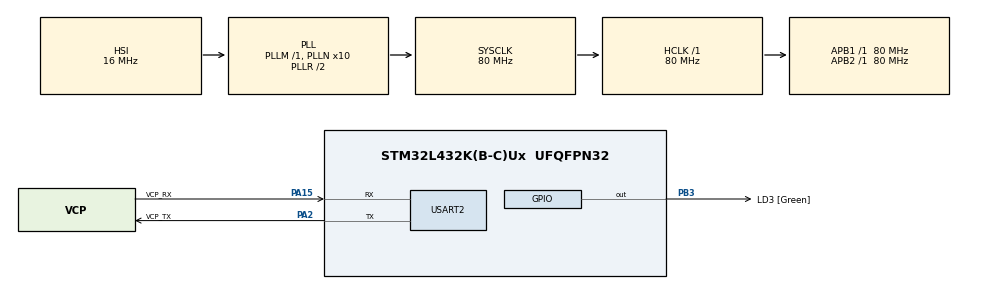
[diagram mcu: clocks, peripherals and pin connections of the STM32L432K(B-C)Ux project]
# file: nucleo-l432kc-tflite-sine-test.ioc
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Mcu.Family=STM32L4
Mcu.Name=STM32L432K(B-C)Ux
Mcu.Package=UFQFPN32
NVIC.PriorityGroup=NVIC_PRIORITYGROUP_4
PA0.GPIO_Label=MCO [High speed clock in]
PA0.Mode=HSE-External-Clock-Source-for-LittleOrca
PA0.Signal=RCC_CK_IN
PA13\ (JTMS-SWDIO).GPIO_Label=SWDIO
PA13\ (JTMS-SWDIO).Mode=Serial_Wire
PA13\ (JTMS-SWDIO).Signal=SYS_JTMS-SWDIO
PA14\ (JTCK-SWCLK).GPIO_Label=SWCLK
PA14\ (JTCK-SWCLK).Mode=Serial_Wire
PA14\ (JTCK-SWCLK).Signal=SYS_JTCK-SWCLK
PA15\ (JTDI).GPIO_Label=VCP_RX
PA15\ (JTDI).Mode=Asynchronous
PA15\ (JTDI).Signal=USART2_RX
PA2.GPIO_Label=VCP_TX
PA2.Mode=Asynchronous
PA2.Signal=USART2_TX
PB3\ (JTDO-TRACESWO).GPIO_Label=LD3 [Green]
PB3\ (JTDO-TRACESWO).Signal=GPIO_Output
PC14-OSC32_IN\ (PC14).Mode=LSE-External-Oscillator
PC14-OSC32_IN\ (PC14).Signal=RCC_OSC32_IN
PC15-OSC32_OUT\ (PC15).Mode=LSE-External-Oscillator
PC15-OSC32_OUT\ (PC15).Signal=RCC_OSC32_OUT
ProjectManager.HeapSize=0x200
ProjectManager.StackSize=0x400
ProjectManager.TargetToolchain=STM32CubeIDE
RCC.ADCFreq_Value=64000000
RCC.AHBFreq_Value=80000000
RCC.APB1Freq_Value=80000000
RCC.APB1TimFreq_Value=80000000
RCC.APB2Freq_Value=80000000
RCC.APB2TimFreq_Value=80000000
RCC.CortexFreq_Value=80000000
RCC.HCLKFreq_Value=80000000
RCC.HSE_VALUE=8000000
RCC.HSI16_VALUE=16000000
RCC.HSI48_VALUE=48000000
RCC.HSI_VALUE=16000000
RCC.MSI_VALUE=4000000
RCC.PLLMUL=RCC_PLLMUL_4
RCC.PLLN=10
RCC.PLLSourceVirtual=RCC_PLLSOURCE_HSI
RCC.SYSCLKFreq_VALUE=80000000
RCC.SYSCLKSource=RCC_SYSCLKSOURCE_PLLCLK
RCC.USBFreq_Value=64000000
RCC.VCOOutputFreq_Value=160000000
TIM16.Prescaler=80 - 1
USART2.VirtualMode-Asynchronous=VM_ASYNC
VP_TIM16_VS_ClockSourceINT.Mode=Enable_Timer
board=NUCLEO-L432KC

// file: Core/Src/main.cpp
/* USER CODE BEGIN Header */
/**
  ******************************************************************************
  * @file           : main.c
  * @brief          : Main program body
  ******************************************************************************
  * @attention
  *
  * <h2><center>&copy; Copyright (c) 2021 STMicroelectronics.
  * All rights reserved.</center></h2>
  *
  * This software component is licensed by ST under BSD 3-Clause license,
  * the "License"; You may not use this file except in compliance with the
  * License. You may obtain a copy of the License at:
  *                        opensource.org/licenses/BSD-3-Clause
  *
  ******************************************************************************
  */
/* USER CODE END Header */
#include "main.h"

/* USER CODE BEGIN Includes */
#include <string.h>

#include "tensorflow/lite/micro/kernels/micro_ops.h"
#include "tensorflow/lite/micro/micro_error_reporter.h"
#include "tensorflow/lite/micro/micro_interpreter.h"
#include "tensorflow/lite/micro/micro_mutable_op_resolver.h"
#include "tensorflow/lite/version.h"
#include "sine_model.h"
/* USER CODE END Includes */

TIM_HandleTypeDef htim16;

UART_HandleTypeDef huart2;

/* USER CODE BEGIN PV */

// TFLite globals
namespace {
  tflite::ErrorReporter* error_reporter = nullptr;
  const tflite::Model* model = nullptr;
  tflite::MicroInterpreter* interpreter = nullptr;
  TfLiteTensor* model_input = nullptr;
  TfLiteTensor* model_output = nullptr;

  // Create an area of memory to use for input, output, and other TensorFlow
  // arrays. You'll need to adjust this by compiling, running, and looking
  // for errors.
  constexpr int kTensorArenaSize = 2 * 1024;
  __attribute__((aligned(16)))uint8_t tensor_arena[kTensorArenaSize];
} // namespace

/* USER CODE END PV */

void SystemClock_Config(void);
static void MX_GPIO_Init(void);
static void MX_USART2_UART_Init(void);
static void MX_TIM16_Init(void);

int main(void)
{
  /* USER CODE BEGIN 1 */
  char buf[50];
  int buf_len = 0;
  TfLiteStatus tflite_status;
  uint32_t num_elements;
  uint32_t timestamp;
  float y_val;

  /* USER CODE END 1 */

  /* MCU Configuration--------------------------------------------------------*/

  /* Reset of all peripherals, Initializes the Flash interface and the Systick. */
  HAL_Init();

  /* Configure the system clock */
  SystemClock_Config();

  /* Initialize all configured peripherals */
  MX_GPIO_Init();
  MX_USART2_UART_Init();
  MX_TIM16_Init();
  /* USER CODE BEGIN 2 */

  // Start timer/counter
  HAL_TIM_Base_Start(&htim16);

  // Set up logging (modify tensorflow/lite/micro/debug_log.cc)
  static tflite::MicroErrorReporter micro_error_reporter;
  error_reporter = &micro_error_reporter;

  // Say something to test error reporter
  error_reporter->Report("STM32 TensorFlow Lite test");

  // Map the model into a usable data structure
  model = tflite::GetModel(sine_model);
  if (model->version() != TFLITE_SCHEMA_VERSION)
  {
    error_reporter->Report("Model version does not match Schema");
    while(1);
  }

  // Pull in only needed operations (should match NN layers). Template parameter
  // <n> is number of ops to be added. Available ops:
  // tensorflow/lite/micro/kernels/micro_ops.h
  static tflite::MicroMutableOpResolver<1> micro_op_resolver;

  // Add dense neural network layer operation
  // KennyKang 20210808
  //tflite_status = micro_op_resolver.AddBuiltin(
  //     tflite::BuiltinOperator_FULLY_CONNECTED,
  //     tflite::ops::micro::Register_FULLY_CONNECTED());
  tflite_status = micro_op_resolver.AddFullyConnected();
  if (tflite_status != kTfLiteOk)
  {
    error_reporter->Report("Could not add FULLY CONNECTED op");
    while(1);
  }

  // Build an interpreter to run the model with.
  static tflite::MicroInterpreter static_interpreter(
      model, micro_op_resolver, tensor_arena, kTensorArenaSize, error_reporter);
  interpreter = &static_interpreter;

  // Allocate memory from the tensor_arena for the model's tensors.
  tflite_status = interpreter->AllocateTensors();
  if (tflite_status != kTfLiteOk)
  {
    error_reporter->Report("AllocateTensors() failed");
    while(1);
  }

  // Assign model input and output buffers (tensors) to pointers
  model_input = interpreter->input(0);
  model_output = interpreter->output(0);

  // Get number of elements in input tensor
  num_elements = model_input->bytes / sizeof(float);
  buf_len = sprintf(buf, "Number of input elements: %lu\r\n", num_elements);
  HAL_UART_Transmit(&huart2, (uint8_t *)buf, buf_len, 100);

  /* USER CODE END 2 */

  /* Infinite loop */
  /* USER CODE BEGIN WHILE */
  while (1)
  {
	  // Fill input buffer (use test value)
	  for (uint32_t i = 0; i < num_elements; i++)
	  {
	     model_input->data.f[i] = 2.0f;
	  }

	  // Get current timestamp
	  timestamp = htim16.Instance->CNT;

	  // Run inference
	  tflite_status = interpreter->Invoke();
	  if (tflite_status != kTfLiteOk)
	  {
	     error_reporter->Report("Invoke failed");
	  }

	  // Read output (predicted y) of neural network
	  y_val = model_output->data.f[0];

	  // Print output of neural network along with inference time (microseconds)
	  buf_len = sprintf(buf,
	                    "Output: %f | Duration: %lu\r\n",
	                    y_val,
	                    htim16.Instance->CNT - timestamp);
	  HAL_UART_Transmit(&huart2, (uint8_t *)buf, buf_len, 100);

	  // Wait before doing it again
	  HAL_Delay(500);

    /* USER CODE END WHILE */

  }
}

void SystemClock_Config(void)
{
  RCC_OscInitTypeDef RCC_OscInitStruct = {0};
  RCC_ClkInitTypeDef RCC_ClkInitStruct = {0};

  /** Configure the main internal regulator output voltage
  */
  if (HAL_PWREx_ControlVoltageScaling(PWR_REGULATOR_VOLTAGE_SCALE1) != HAL_OK)
  {
    Error_Handler();
  }
  /** Initializes the RCC Oscillators according to the specified parameters
  * in the RCC_OscInitTypeDef structure.
  */
  RCC_OscInitStruct.OscillatorType = RCC_OSCILLATORTYPE_HSI;
  RCC_OscInitStruct.HSIState = RCC_HSI_ON;
  RCC_OscInitStruct.HSICalibrationValue = RCC_HSICALIBRATION_DEFAULT;
  RCC_OscInitStruct.PLL.PLLState = RCC_PLL_ON;
  RCC_OscInitStruct.PLL.PLLSource = RCC_PLLSOURCE_HSI;
  RCC_OscInitStruct.PLL.PLLM = 1;
  RCC_OscInitStruct.PLL.PLLN = 10;
  RCC_OscInitStruct.PLL.PLLP = RCC_PLLP_DIV7;
  RCC_OscInitStruct.PLL.PLLQ = RCC_PLLQ_DIV2;
  RCC_OscInitStruct.PLL.PLLR = RCC_PLLR_DIV2;
  if (HAL_RCC_OscConfig(&RCC_OscInitStruct) != HAL_OK)
  {
    Error_Handler();
  }
  /** Initializes the CPU, AHB and APB buses clocks
  */
  RCC_ClkInitStruct.ClockType = RCC_CLOCKTYPE_HCLK|RCC_CLOCKTYPE_SYSCLK
                              |RCC_CLOCKTYPE_PCLK1|RCC_CLOCKTYPE_PCLK2;
  RCC_ClkInitStruct.SYSCLKSource = RCC_SYSCLKSOURCE_PLLCLK;
  RCC_ClkInitStruct.AHBCLKDivider = RCC_SYSCLK_DIV1;
  RCC_ClkInitStruct.APB1CLKDivider = RCC_HCLK_DIV1;
  RCC_ClkInitStruct.APB2CLKDivider = RCC_HCLK_DIV1;

  if (HAL_RCC_ClockConfig(&RCC_ClkInitStruct, FLASH_LATENCY_4) != HAL_OK)
  {
    Error_Handler();
  }
}

static void MX_TIM16_Init(void)
{

  htim16.Instance = TIM16;
  htim16.Init.Prescaler = 80 - 1;
  htim16.Init.CounterMode = TIM_COUNTERMODE_UP;
  htim16.Init.Period = 65535;
  htim16.Init.ClockDivision = TIM_CLOCKDIVISION_DIV1;
  htim16.Init.RepetitionCounter = 0;
  htim16.Init.AutoReloadPreload = TIM_AUTORELOAD_PRELOAD_DISABLE;
  if (HAL_TIM_Base_Init(&htim16) != HAL_OK)
  {
    Error_Handler();
  }

}

static void MX_USART2_UART_Init(void)
{

  huart2.Instance = USART2;
  huart2.Init.BaudRate = 115200;
  huart2.Init.WordLength = UART_WORDLENGTH_8B;
  huart2.Init.StopBits = UART_STOPBITS_1;
  huart2.Init.Parity = UART_PARITY_NONE;
  huart2.Init.Mode = UART_MODE_TX_RX;
  huart2.Init.HwFlowCtl = UART_HWCONTROL_NONE;
  huart2.Init.OverSampling = UART_OVERSAMPLING_16;
  huart2.Init.OneBitSampling = UART_ONE_BIT_SAMPLE_DISABLE;
  huart2.AdvancedInit.AdvFeatureInit = UART_ADVFEATURE_NO_INIT;
  if (HAL_UART_Init(&huart2) != HAL_OK)
  {
    Error_Handler();
  }

}

static void MX_GPIO_Init(void)
{
  GPIO_InitTypeDef GPIO_InitStruct = {0};

  /* GPIO Ports Clock Enable */
  __HAL_RCC_GPIOC_CLK_ENABLE();
  __HAL_RCC_GPIOA_CLK_ENABLE();
  __HAL_RCC_GPIOB_CLK_ENABLE();

  /*Configure GPIO pin Output Level */
  HAL_GPIO_WritePin(LD3_GPIO_Port, LD3_Pin, GPIO_PIN_RESET);

  /*Configure GPIO pin : LD3_Pin */
  GPIO_InitStruct.Pin = LD3_Pin;
  GPIO_InitStruct.Mode = GPIO_MODE_OUTPUT_PP;
  GPIO_InitStruct.Pull = GPIO_NOPULL;
  GPIO_InitStruct.Speed = GPIO_SPEED_FREQ_LOW;
  HAL_GPIO_Init(LD3_GPIO_Port, &GPIO_InitStruct);

}

/* USER CODE BEGIN 4 */

// Custom implementation of DebugLog from TensorFlow
extern "C" void DebugLog(const char* s)
{
  HAL_UART_Transmit(&huart2, (uint8_t *)s, strlen(s), 100);
}

/* USER CODE END 4 */

void Error_Handler(void)
{
  __disable_irq();
  while (1)
  {
  }
}

/************************ (C) COPYRIGHT STMicroelectronics *****END OF FILE****/
